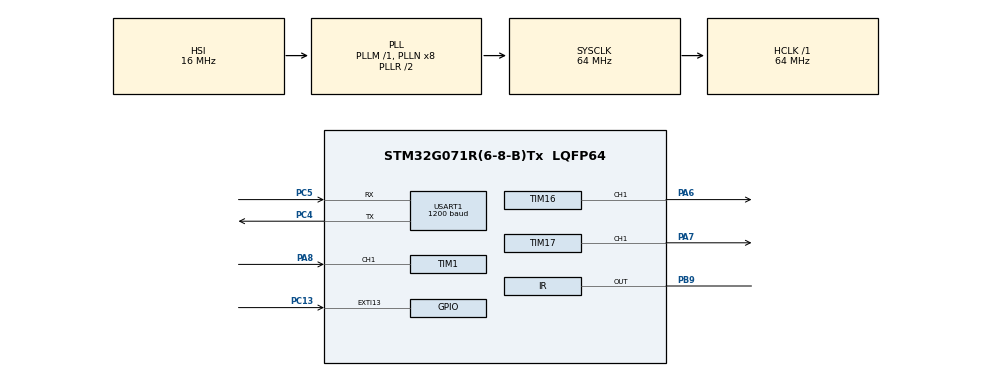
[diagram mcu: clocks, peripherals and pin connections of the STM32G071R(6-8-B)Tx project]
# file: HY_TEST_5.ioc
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IRTIM.InputSelection=HAL_SYSCFG_IRDA_ENV_SEL_TIM16
IRTIM.Polarity=HAL_SYSCFG_IRDA_POLARITY_NOT_INVERTED
Mcu.Family=STM32G0
Mcu.Name=STM32G071R(6-8-B)Tx
Mcu.Package=LQFP64
NVIC.EXTI4_15_IRQn=true\:0\:0\:false\:false\:true\:true\:true
PA6.Signal=S_TIM16_CH1
PA7.Signal=S_TIM17_CH1
PA8.Signal=S_TIM1_CH1
PB9.Mode=INFRARED
PB9.Signal=IR_OUT
PC13.GPIO_ModeDefaultEXTI=GPIO_MODE_IT_RISING_FALLING
PC13.GPIO_PuPd=GPIO_NOPULL
PC13.Signal=GPXTI13
PC4.GPIO_ModeDefaultPP=GPIO_MODE_AF_PP
PC4.GPIO_PuPd=GPIO_NOPULL
PC4.GPIO_Speed=GPIO_SPEED_FREQ_LOW
PC4.Mode=IrDA
PC4.PinState=GPIO_PIN_RESET
PC4.Signal=USART1_TX
PC5.GPIO_ModeDefaultPP=GPIO_MODE_AF_PP
PC5.GPIO_PuPd=GPIO_NOPULL
PC5.GPIO_Speed=GPIO_SPEED_FREQ_LOW
PC5.Mode=IrDA
PC5.PinState=GPIO_PIN_RESET
PC5.Signal=USART1_RX
ProjectManager.HeapSize=0x200
ProjectManager.StackSize=0x400
ProjectManager.TargetToolchain=MDK-ARM V5.27
RCC.ADCFreq_Value=64000000
RCC.AHBFreq_Value=64000000
RCC.CortexFreq_Value=64000000
RCC.EXTERNAL_CLOCK_VALUE=48000
RCC.HCLKFreq_Value=64000000
RCC.HSE_VALUE=8000000
RCC.HSI_VALUE=16000000
RCC.LSE_VALUE=32768
RCC.SYSCLKFreq_VALUE=64000000
RCC.SYSCLKSource=RCC_SYSCLKSOURCE_PLLCLK
RCC.VCOOutputFreq_Value=128000000
SH.S_TIM16_CH1.0=TIM16_CH1,PWM Generation1 CH1
SH.S_TIM17_CH1.0=TIM17_CH1,PWM Generation1 CH1
SH.S_TIM1_CH1.0=TIM1_CH1,Input_Capture1_from_TI1
TIM1.Channel-Input_Capture1_from_TI1=TIM_CHANNEL_1
TIM16.Channel=TIM_CHANNEL_1
TIM16.Period=320
TIM16.Prescaler=127
TIM16.Pulse=160
TIM17.Channel=TIM_CHANNEL_1
TIM17.Period=16
TIM17.Prescaler=127
TIM17.Pulse=8
USART1.BaudRate=1200
USART1.VirtualMode-IrDA=VM_IRDA
VP_SYS_VS_DBSignals.Mode=DisableDeadBatterySignals
VP_TIM16_VS_ClockSourceINT.Mode=Enable_Timer
VP_TIM17_VS_ClockSourceINT.Mode=Enable_Timer
board=custom

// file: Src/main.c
/* USER CODE BEGIN Header */
/**
  ******************************************************************************
  * @file           : main.c
  * @brief          : Main program body
  ******************************************************************************
  * @attention
  *
  * <h2><center>&copy; Copyright (c) 2021 STMicroelectronics.
  * All rights reserved.</center></h2>
  *
  * This software component is licensed by ST under BSD 3-Clause license,
  * the "License"; You may not use this file except in compliance with the
  * License. You may obtain a copy of the License at:
  *                        opensource.org/licenses/BSD-3-Clause
  *
  ******************************************************************************
  */
/* USER CODE END Header */
#include "main.h"

TIM_HandleTypeDef htim1;
TIM_HandleTypeDef htim16;
TIM_HandleTypeDef htim17;

IRDA_HandleTypeDef hirda1;

void SystemClock_Config(void);
static void MX_GPIO_Init(void);
static void MX_IRTIM_Init(void);
static void MX_TIM17_Init(void);
static void MX_USART1_IRDA_Init(void);
static void MX_TIM1_Init(void);
static void MX_TIM16_Init(void);

int main(void)
{

  /* MCU Configuration--------------------------------------------------------*/

  /* Reset of all peripherals, Initializes the Flash interface and the Systick. */
  HAL_Init();

  /* Configure the system clock */
  SystemClock_Config();

  /* Initialize all configured peripherals */
  MX_GPIO_Init();
  MX_IRTIM_Init();
  MX_TIM17_Init();
  MX_USART1_IRDA_Init();
  MX_TIM1_Init();
  MX_TIM16_Init();
  /* USER CODE BEGIN 2 */
	HAL_TIM_PWM_Start(&htim16,TIM_CHANNEL_1);
	HAL_TIM_PWM_Start(&htim17,TIM_CHANNEL_1);
  /* USER CODE END 2 */

  /* Infinite loop */
  while (1)
  {

  }
}

void SystemClock_Config(void)
{
  RCC_OscInitTypeDef RCC_OscInitStruct = {0};
  RCC_ClkInitTypeDef RCC_ClkInitStruct = {0};
  RCC_PeriphCLKInitTypeDef PeriphClkInit = {0};

  /** Configure the main internal regulator output voltage
  */
  HAL_PWREx_ControlVoltageScaling(PWR_REGULATOR_VOLTAGE_SCALE1);
  /** Initializes the RCC Oscillators according to the specified parameters
  * in the RCC_OscInitTypeDef structure.
  */
  RCC_OscInitStruct.OscillatorType = RCC_OSCILLATORTYPE_HSI;
  RCC_OscInitStruct.HSIState = RCC_HSI_ON;
  RCC_OscInitStruct.HSIDiv = RCC_HSI_DIV1;
  RCC_OscInitStruct.HSICalibrationValue = RCC_HSICALIBRATION_DEFAULT;
  RCC_OscInitStruct.PLL.PLLState = RCC_PLL_ON;
  RCC_OscInitStruct.PLL.PLLSource = RCC_PLLSOURCE_HSI;
  RCC_OscInitStruct.PLL.PLLM = RCC_PLLM_DIV1;
  RCC_OscInitStruct.PLL.PLLN = 8;
  RCC_OscInitStruct.PLL.PLLP = RCC_PLLP_DIV2;
  RCC_OscInitStruct.PLL.PLLQ = RCC_PLLQ_DIV2;
  RCC_OscInitStruct.PLL.PLLR = RCC_PLLR_DIV2;
  if (HAL_RCC_OscConfig(&RCC_OscInitStruct) != HAL_OK)
  {
    Error_Handler();
  }
  /** Initializes the CPU, AHB and APB buses clocks
  */
  RCC_ClkInitStruct.ClockType = RCC_CLOCKTYPE_HCLK|RCC_CLOCKTYPE_SYSCLK
                              |RCC_CLOCKTYPE_PCLK1;
  RCC_ClkInitStruct.SYSCLKSource = RCC_SYSCLKSOURCE_PLLCLK;
  RCC_ClkInitStruct.AHBCLKDivider = RCC_SYSCLK_DIV1;
  RCC_ClkInitStruct.APB1CLKDivider = RCC_HCLK_DIV1;

  if (HAL_RCC_ClockConfig(&RCC_ClkInitStruct, FLASH_LATENCY_2) != HAL_OK)
  {
    Error_Handler();
  }
  /** Initializes the peripherals clocks
  */
  PeriphClkInit.PeriphClockSelection = RCC_PERIPHCLK_USART1|RCC_PERIPHCLK_TIM1;
  PeriphClkInit.Usart1ClockSelection = RCC_USART1CLKSOURCE_PCLK1;
  PeriphClkInit.Tim1ClockSelection = RCC_TIM1CLKSOURCE_PCLK1;
  if (HAL_RCCEx_PeriphCLKConfig(&PeriphClkInit) != HAL_OK)
  {
    Error_Handler();
  }
}

static void MX_IRTIM_Init(void)
{

  __HAL_SYSCFG_IRDA_ENV_SELECTION(HAL_SYSCFG_IRDA_ENV_SEL_TIM16);
  __HAL_SYSCFG_IRDA_OUT_POLARITY_SELECTION(HAL_SYSCFG_IRDA_POLARITY_NOT_INVERTED);

}

static void MX_TIM1_Init(void)
{

  TIM_MasterConfigTypeDef sMasterConfig = {0};
  TIM_IC_InitTypeDef sConfigIC = {0};
  TIM_BreakDeadTimeConfigTypeDef sBreakDeadTimeConfig = {0};

  htim1.Instance = TIM1;
  htim1.Init.Prescaler = 0;
  htim1.Init.CounterMode = TIM_COUNTERMODE_UP;
  htim1.Init.Period = 65535;
  htim1.Init.ClockDivision = TIM_CLOCKDIVISION_DIV1;
  htim1.Init.RepetitionCounter = 0;
  htim1.Init.AutoReloadPreload = TIM_AUTORELOAD_PRELOAD_DISABLE;
  if (HAL_TIM_IC_Init(&htim1) != HAL_OK)
  {
    Error_Handler();
  }
  sMasterConfig.MasterOutputTrigger = TIM_TRGO_RESET;
  sMasterConfig.MasterOutputTrigger2 = TIM_TRGO2_RESET;
  sMasterConfig.MasterSlaveMode = TIM_MASTERSLAVEMODE_DISABLE;
  if (HAL_TIMEx_MasterConfigSynchronization(&htim1, &sMasterConfig) != HAL_OK)
  {
    Error_Handler();
  }
  sConfigIC.ICPolarity = TIM_INPUTCHANNELPOLARITY_RISING;
  sConfigIC.ICSelection = TIM_ICSELECTION_DIRECTTI;
  sConfigIC.ICPrescaler = TIM_ICPSC_DIV1;
  sConfigIC.ICFilter = 0;
  if (HAL_TIM_IC_ConfigChannel(&htim1, &sConfigIC, TIM_CHANNEL_1) != HAL_OK)
  {
    Error_Handler();
  }
  sBreakDeadTimeConfig.BreakAFMode = TIM_BREAK_AFMODE_INPUT;
  sBreakDeadTimeConfig.Break2AFMode = TIM_BREAK_AFMODE_INPUT;
  if (HAL_TIMEx_ConfigBreakDeadTime(&htim1, &sBreakDeadTimeConfig) != HAL_OK)
  {
    Error_Handler();
  }

}

static void MX_TIM16_Init(void)
{

  TIM_OC_InitTypeDef sConfigOC = {0};
  TIM_BreakDeadTimeConfigTypeDef sBreakDeadTimeConfig = {0};

  htim16.Instance = TIM16;
  htim16.Init.Prescaler = 127;
  htim16.Init.CounterMode = TIM_COUNTERMODE_UP;
  htim16.Init.Period = 320;
  htim16.Init.ClockDivision = TIM_CLOCKDIVISION_DIV1;
  htim16.Init.RepetitionCounter = 0;
  htim16.Init.AutoReloadPreload = TIM_AUTORELOAD_PRELOAD_DISABLE;
  if (HAL_TIM_Base_Init(&htim16) != HAL_OK)
  {
    Error_Handler();
  }
  if (HAL_TIM_PWM_Init(&htim16) != HAL_OK)
  {
    Error_Handler();
  }
  sConfigOC.OCMode = TIM_OCMODE_PWM1;
  sConfigOC.Pulse = 160;
  sConfigOC.OCPolarity = TIM_OCPOLARITY_HIGH;
  sConfigOC.OCNPolarity = TIM_OCNPOLARITY_HIGH;
  sConfigOC.OCFastMode = TIM_OCFAST_DISABLE;
  sConfigOC.OCIdleState = TIM_OCIDLESTATE_RESET;
  sConfigOC.OCNIdleState = TIM_OCNIDLESTATE_RESET;
  if (HAL_TIM_PWM_ConfigChannel(&htim16, &sConfigOC, TIM_CHANNEL_1) != HAL_OK)
  {
    Error_Handler();
  }
  sBreakDeadTimeConfig.OffStateRunMode = TIM_OSSR_DISABLE;
  sBreakDeadTimeConfig.OffStateIDLEMode = TIM_OSSI_DISABLE;
  sBreakDeadTimeConfig.LockLevel = TIM_LOCKLEVEL_OFF;
  sBreakDeadTimeConfig.DeadTime = 0;
  sBreakDeadTimeConfig.BreakState = TIM_BREAK_DISABLE;
  sBreakDeadTimeConfig.BreakPolarity = TIM_BREAKPOLARITY_HIGH;
  sBreakDeadTimeConfig.BreakFilter = 0;
  sBreakDeadTimeConfig.AutomaticOutput = TIM_AUTOMATICOUTPUT_DISABLE;
  if (HAL_TIMEx_ConfigBreakDeadTime(&htim16, &sBreakDeadTimeConfig) != HAL_OK)
  {
    Error_Handler();
  }
  HAL_TIM_MspPostInit(&htim16);

}

static void MX_TIM17_Init(void)
{

  TIM_OC_InitTypeDef sConfigOC = {0};
  TIM_BreakDeadTimeConfigTypeDef sBreakDeadTimeConfig = {0};

  htim17.Instance = TIM17;
  htim17.Init.Prescaler = 127;
  htim17.Init.CounterMode = TIM_COUNTERMODE_UP;
  htim17.Init.Period = 16;
  htim17.Init.ClockDivision = TIM_CLOCKDIVISION_DIV1;
  htim17.Init.RepetitionCounter = 0;
  htim17.Init.AutoReloadPreload = TIM_AUTORELOAD_PRELOAD_DISABLE;
  if (HAL_TIM_Base_Init(&htim17) != HAL_OK)
  {
    Error_Handler();
  }
  if (HAL_TIM_PWM_Init(&htim17) != HAL_OK)
  {
    Error_Handler();
  }
  sConfigOC.OCMode = TIM_OCMODE_PWM1;
  sConfigOC.Pulse = 8;
  sConfigOC.OCPolarity = TIM_OCPOLARITY_HIGH;
  sConfigOC.OCNPolarity = TIM_OCNPOLARITY_HIGH;
  sConfigOC.OCFastMode = TIM_OCFAST_DISABLE;
  sConfigOC.OCIdleState = TIM_OCIDLESTATE_RESET;
  sConfigOC.OCNIdleState = TIM_OCNIDLESTATE_RESET;
  if (HAL_TIM_PWM_ConfigChannel(&htim17, &sConfigOC, TIM_CHANNEL_1) != HAL_OK)
  {
    Error_Handler();
  }
  sBreakDeadTimeConfig.OffStateRunMode = TIM_OSSR_DISABLE;
  sBreakDeadTimeConfig.OffStateIDLEMode = TIM_OSSI_DISABLE;
  sBreakDeadTimeConfig.LockLevel = TIM_LOCKLEVEL_OFF;
  sBreakDeadTimeConfig.DeadTime = 0;
  sBreakDeadTimeConfig.BreakState = TIM_BREAK_DISABLE;
  sBreakDeadTimeConfig.BreakPolarity = TIM_BREAKPOLARITY_HIGH;
  sBreakDeadTimeConfig.BreakFilter = 0;
  sBreakDeadTimeConfig.AutomaticOutput = TIM_AUTOMATICOUTPUT_DISABLE;
  if (HAL_TIMEx_ConfigBreakDeadTime(&htim17, &sBreakDeadTimeConfig) != HAL_OK)
  {
    Error_Handler();
  }
  HAL_TIM_MspPostInit(&htim17);

}

static void MX_USART1_IRDA_Init(void)
{

  hirda1.Instance = USART1;
  hirda1.Init.BaudRate = 1200;
  hirda1.Init.WordLength = IRDA_WORDLENGTH_8B;
  hirda1.Init.Parity = IRDA_PARITY_NONE;
  hirda1.Init.Mode = IRDA_MODE_TX_RX;
  hirda1.Init.Prescaler = 10;
  hirda1.Init.PowerMode = IRDA_POWERMODE_NORMAL;
  hirda1.Init.ClockPrescaler = IRDA_PRESCALER_DIV1;
  if (HAL_IRDA_Init(&hirda1) != HAL_OK)
  {
    Error_Handler();
  }

}

static void MX_GPIO_Init(void)
{
  GPIO_InitTypeDef GPIO_InitStruct = {0};

  /* GPIO Ports Clock Enable */
  __HAL_RCC_GPIOC_CLK_ENABLE();
  __HAL_RCC_GPIOA_CLK_ENABLE();
  __HAL_RCC_GPIOB_CLK_ENABLE();

  /*Configure GPIO pin : PC13 */
  GPIO_InitStruct.Pin = GPIO_PIN_13;
  GPIO_InitStruct.Mode = GPIO_MODE_IT_RISING_FALLING;
  GPIO_InitStruct.Pull = GPIO_NOPULL;
  HAL_GPIO_Init(GPIOC, &GPIO_InitStruct);

  /*Configure GPIO pin : PB9 */
  GPIO_InitStruct.Pin = GPIO_PIN_9;
  GPIO_InitStruct.Mode = GPIO_MODE_AF_PP;
  GPIO_InitStruct.Pull = GPIO_NOPULL;
  GPIO_InitStruct.Speed = GPIO_SPEED_FREQ_LOW;
  GPIO_InitStruct.Alternate = GPIO_AF0_IR;
  HAL_GPIO_Init(GPIOB, &GPIO_InitStruct);

  /* EXTI interrupt init*/
  HAL_NVIC_SetPriority(EXTI4_15_IRQn, 0, 0);
  HAL_NVIC_EnableIRQ(EXTI4_15_IRQn);

}

/* USER CODE BEGIN 4 */

void HAL_GPIO_EXTI_Falling_Callback(uint16_t GPIO_Pin)
{
	if(GPIO_Pin == GPIO_PIN_13)
	{
	HAL_TIM_PWM_Start(&htim16,TIM_CHANNEL_1);
	}
}

void HAL_GPIO_EXTI_Rising_Callback(uint16_t GPIO_Pin)
{
  if(GPIO_Pin == GPIO_PIN_13)
	{
	  HAL_TIM_PWM_Stop(&htim16,TIM_CHANNEL_1);
	}
}

/* USER CODE END 4 */

void Error_Handler(void)
{
  __disable_irq();
  while (1)
  {
  }
}

/************************ (C) COPYRIGHT STMicroelectronics *****END OF FILE****/
